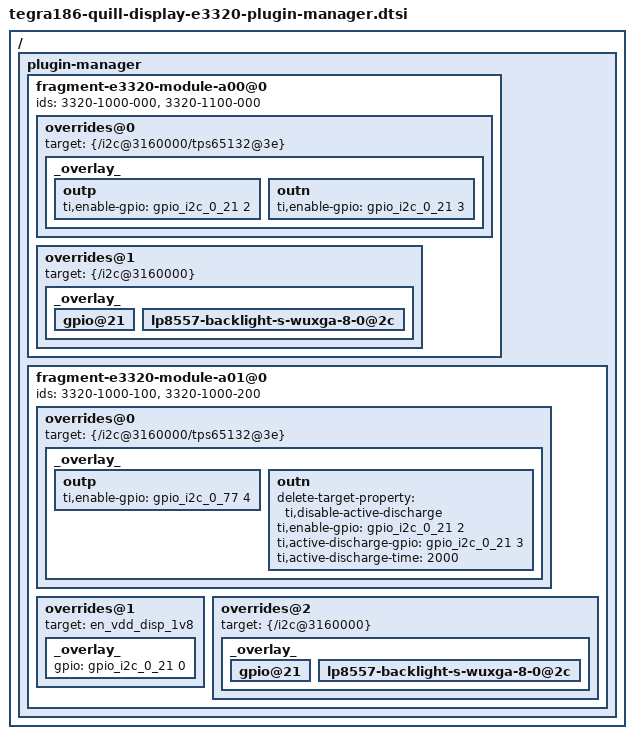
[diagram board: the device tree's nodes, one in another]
/*
 * tegra186-quill-display-e3320-plugin-manager.dtsi: E3320 Display module
 * override DTSI file.
 *
 * Copyright (c) 2017, NVIDIA CORPORATION. All rights reserved.
 *
 * This program is free software; you can redistribute it and/or modify
 * it under the terms of the GNU General Public License as published by
 * the Free Software Foundation; version 2 of the License.
 *
 * This program is distributed in the hope that it will be useful, but WITHOUT
 * ANY WARRANTY; without even the implied warranty of MERCHANTABILITY or
 * FITNESS FOR A PARTICULAR PURPOSE.  See the GNU General Public License for
 * more details.
 */

/ {
	plugin-manager {
		fragment-e3320-module-a00@0 {
			ids = "3320-1000-000", "3320-1100-000";
			overrides@0 {
				target = <&{/i2c@3160000/tps65132@3e}>;
				_overlay_ {
					status = "okay";
					outp {
						ti,enable-gpio = <&gpio_i2c_0_21 2 0>;
					};
					outn {
						ti,enable-gpio = <&gpio_i2c_0_21 3 0>;
					};
				};
			};

			overrides@1 {
				target = <&{/i2c@3160000}>;
				_overlay_ {
					gpio@21 {
						status = "okay";
					};
					lp8557-backlight-s-wuxga-8-0@2c {
						status = "okay";
					};
				};
			};
		};

		fragment-e3320-module-a01@0 {
			ids = "3320-1000-100", "3320-1000-200";
			overrides@0 {
				target = <&{/i2c@3160000/tps65132@3e}>;
				_overlay_ {
					status = "okay";
					outp {
						ti,enable-gpio = <&gpio_i2c_0_77 4 0>;
					};
					outn {
						delete-target-property = "ti,disable-active-discharge";
						ti,enable-gpio = <&gpio_i2c_0_21 2 0>;
						ti,active-discharge-gpio = <&gpio_i2c_0_21 3 0>;
						ti,active-discharge-time = <2000>; /* in us */
					};
				};
			};

			overrides@1 {
				target = <&en_vdd_disp_1v8>;
				_overlay_ {
					gpio = <&gpio_i2c_0_21 0 0>;
				};
			};

			overrides@2 {
				target = <&{/i2c@3160000}>;
				_overlay_ {
					gpio@21 {
						status = "okay";
					};
					lp8557-backlight-s-wuxga-8-0@2c {
						status = "okay";
					};
				};
			};
		};
	};
};

